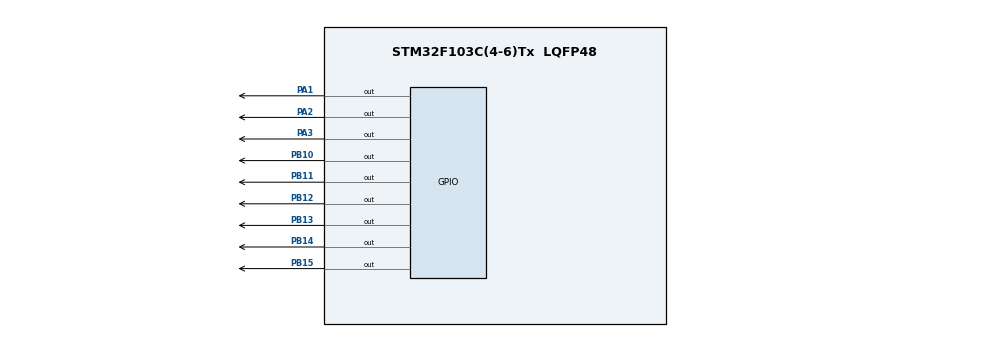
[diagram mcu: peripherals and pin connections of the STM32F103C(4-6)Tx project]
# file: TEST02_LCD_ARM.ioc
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Mcu.Family=STM32F1
Mcu.Name=STM32F103C(4-6)Tx
Mcu.Package=LQFP48
NVIC.PriorityGroup=NVIC_PRIORITYGROUP_4
PA1.Signal=GPIO_Output
PA2.Signal=GPIO_Output
PA3.Signal=GPIO_Output
PB10.Signal=GPIO_Output
PB11.Signal=GPIO_Output
PB12.Signal=GPIO_Output
PB13.Signal=GPIO_Output
PB14.Signal=GPIO_Output
PB15.Signal=GPIO_Output
PD0-OSC_IN.Mode=HSE-External-Oscillator
PD0-OSC_IN.Signal=RCC_OSC_IN
PD1-OSC_OUT.Mode=HSE-External-Oscillator
PD1-OSC_OUT.Signal=RCC_OSC_OUT
ProjectManager.HeapSize=0x200
ProjectManager.StackSize=0x400
ProjectManager.TargetToolchain=STM32CubeIDE
RCC.APB1Freq_Value=8000000
RCC.APB2Freq_Value=8000000
VP_SYS_VS_ND.Mode=No_Debug
board=custom

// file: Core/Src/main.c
/* USER CODE BEGIN Header */
/**
  ******************************************************************************
  * @file           : main.c
  * @brief          : Main program body
  ******************************************************************************
  * @attention
  *
  * Copyright (c) 2023 STMicroelectronics.
  * All rights reserved.
  *
  * This software is licensed under terms that can be found in the LICENSE file
  * in the root directory of this software component.
  * If no LICENSE file comes with this software, it is provided AS-IS.
  *
  ******************************************************************************
  */
/* USER CODE END Header */
#include "main.h"
#include "LCD_INTERFACE.h"

void SystemClock_Config(void);
static void MX_GPIO_Init(void);

int main(void)
{

  /* MCU Configuration--------------------------------------------------------*/

  /* Reset of all peripherals, Initializes the Flash interface and the Systick. */
  HAL_Init();

  /* Configure the system clock */
  SystemClock_Config();

  /* Initialize all configured peripherals */
  MX_GPIO_Init();
  /* USER CODE BEGIN 2 */
  LCD_voidInitialization();
  LCD_voidPuts(0, 0, "Welcome to STM32");
  LCD_voidPuts(1, 0, "Hello Hosny & Tariq");
  LCD_voidPuts(2, 0, "Hello Sherbiny");
  LCD_voidPuts(3, 0, "Hello Hossam");

  /* USER CODE END 2 */

  /* Infinite loop */
  while (1)
  {

    /* USER CODE BEGIN 3 */
	  HAL_GPIO_WritePin(GPIOA, GPIO_PIN_1, GPIO_PIN_SET);
	  HAL_GPIO_WritePin(GPIOA, GPIO_PIN_2, GPIO_PIN_SET);
	  HAL_GPIO_WritePin(GPIOA, GPIO_PIN_3, GPIO_PIN_SET);
	  HAL_Delay(1500);
	  // Blinking LEDs
	  HAL_GPIO_WritePin(GPIOA, GPIO_PIN_1, GPIO_PIN_RESET);
	  HAL_GPIO_WritePin(GPIOA, GPIO_PIN_2, GPIO_PIN_RESET);
	  HAL_GPIO_WritePin(GPIOA, GPIO_PIN_3, GPIO_PIN_RESET);
	  HAL_Delay(1500);

  }
  /* USER CODE END 3 */
}

void SystemClock_Config(void)
{
  RCC_OscInitTypeDef RCC_OscInitStruct = {0};
  RCC_ClkInitTypeDef RCC_ClkInitStruct = {0};

  /** Initializes the RCC Oscillators according to the specified parameters
  * in the RCC_OscInitTypeDef structure.
  */
  RCC_OscInitStruct.OscillatorType = RCC_OSCILLATORTYPE_HSI;
  RCC_OscInitStruct.HSIState = RCC_HSI_ON;
  RCC_OscInitStruct.HSICalibrationValue = RCC_HSICALIBRATION_DEFAULT;
  RCC_OscInitStruct.PLL.PLLState = RCC_PLL_NONE;
  if (HAL_RCC_OscConfig(&RCC_OscInitStruct) != HAL_OK)
  {
    Error_Handler();
  }

  /** Initializes the CPU, AHB and APB buses clocks
  */
  RCC_ClkInitStruct.ClockType = RCC_CLOCKTYPE_HCLK|RCC_CLOCKTYPE_SYSCLK
                              |RCC_CLOCKTYPE_PCLK1|RCC_CLOCKTYPE_PCLK2;
  RCC_ClkInitStruct.SYSCLKSource = RCC_SYSCLKSOURCE_HSI;
  RCC_ClkInitStruct.AHBCLKDivider = RCC_SYSCLK_DIV1;
  RCC_ClkInitStruct.APB1CLKDivider = RCC_HCLK_DIV1;
  RCC_ClkInitStruct.APB2CLKDivider = RCC_HCLK_DIV1;

  if (HAL_RCC_ClockConfig(&RCC_ClkInitStruct, FLASH_LATENCY_0) != HAL_OK)
  {
    Error_Handler();
  }
}

static void MX_GPIO_Init(void)
{
  GPIO_InitTypeDef GPIO_InitStruct = {0};

  /* GPIO Ports Clock Enable */
  __HAL_RCC_GPIOD_CLK_ENABLE();
  __HAL_RCC_GPIOA_CLK_ENABLE();
  __HAL_RCC_GPIOB_CLK_ENABLE();

  /*Configure GPIO pin Output Level */
  HAL_GPIO_WritePin(GPIOA, GPIO_PIN_1|GPIO_PIN_2|GPIO_PIN_3, GPIO_PIN_RESET);

  /*Configure GPIO pin Output Level */
  HAL_GPIO_WritePin(GPIOB, GPIO_PIN_10|GPIO_PIN_11|GPIO_PIN_12|GPIO_PIN_13
                          |GPIO_PIN_14|GPIO_PIN_15, GPIO_PIN_RESET);

  /*Configure GPIO pins : PA1 PA2 PA3 */
  GPIO_InitStruct.Pin = GPIO_PIN_1|GPIO_PIN_2|GPIO_PIN_3;
  GPIO_InitStruct.Mode = GPIO_MODE_OUTPUT_PP;
  GPIO_InitStruct.Pull = GPIO_NOPULL;
  GPIO_InitStruct.Speed = GPIO_SPEED_FREQ_LOW;
  HAL_GPIO_Init(GPIOA, &GPIO_InitStruct);

  /*Configure GPIO pins : PB10 PB11 PB12 PB13
                           PB14 PB15 */
  GPIO_InitStruct.Pin = GPIO_PIN_10|GPIO_PIN_11|GPIO_PIN_12|GPIO_PIN_13
                          |GPIO_PIN_14|GPIO_PIN_15;
  GPIO_InitStruct.Mode = GPIO_MODE_OUTPUT_PP;
  GPIO_InitStruct.Pull = GPIO_NOPULL;
  GPIO_InitStruct.Speed = GPIO_SPEED_FREQ_LOW;
  HAL_GPIO_Init(GPIOB, &GPIO_InitStruct);

}

void Error_Handler(void)
{
  __disable_irq();
  while (1)
  {
  }
}
